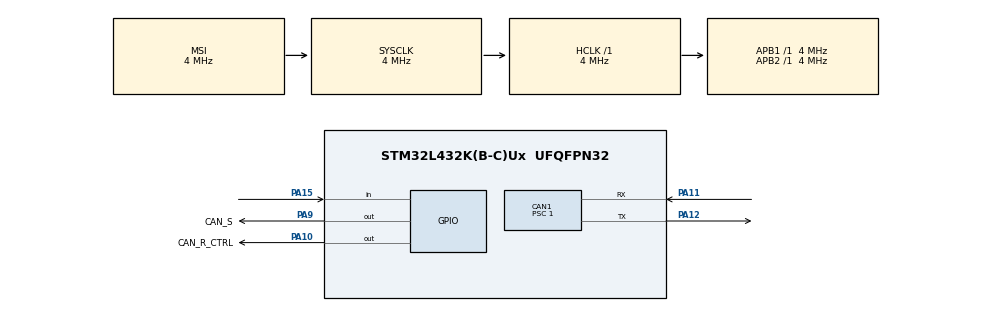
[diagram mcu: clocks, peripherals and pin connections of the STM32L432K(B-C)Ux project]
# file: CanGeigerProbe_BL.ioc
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CAN1.BS1=CAN_BS1_6TQ
CAN1.CalculateBaudRate=500000
CAN1.CalculateTimeBit=2000
CAN1.CalculateTimeQuantum=250.0
CAN1.NART=ENABLE
CAN1.Prescaler=1
Mcu.Family=STM32L4
Mcu.Name=STM32L432K(B-C)Ux
Mcu.Package=UFQFPN32
NVIC.CAN1_RX0_IRQn=true\:0\:0\:false\:false\:true\:true\:true\:true
NVIC.CAN1_TX_IRQn=true\:0\:0\:false\:false\:true\:true\:true\:true
NVIC.PriorityGroup=NVIC_PRIORITYGROUP_4
PA10.GPIO_Label=CAN_R_CTRL
PA10.Signal=GPIO_Output
PA11.Mode=CAN_Activate
PA11.Signal=CAN1_RX
PA12.Mode=CAN_Activate
PA12.Signal=CAN1_TX
PA13\ (JTMS-SWDIO).GPIO_Label=SWDIO
PA13\ (JTMS-SWDIO).Mode=Trace_Asynchronous_SW
PA13\ (JTMS-SWDIO).Signal=SYS_JTMS-SWDIO
PA14\ (JTCK-SWCLK).GPIO_Label=SWCLK
PA14\ (JTCK-SWCLK).Mode=Trace_Asynchronous_SW
PA14\ (JTCK-SWCLK).Signal=SYS_JTCK-SWCLK
PA15\ (JTDI).Signal=GPIO_Input
PA9.GPIO_Label=CAN_S
PA9.Signal=GPIO_Output
PB3\ (JTDO-TRACESWO).GPIO_Label=SWO
PB3\ (JTDO-TRACESWO).Mode=Trace_Asynchronous_SW
PB3\ (JTDO-TRACESWO).Signal=SYS_JTDO-SWO
ProjectManager.HeapSize=0x200
ProjectManager.StackSize=0x400
ProjectManager.TargetToolchain=STM32CubeIDE
RCC.ADCCLockSelection=RCC_ADCCLKSOURCE_SYSCLK
RCC.ADCFreq_Value=4000000
RCC.AHBFreq_Value=4000000
RCC.APB1Freq_Value=4000000
RCC.APB1TimFreq_Value=4000000
RCC.APB2Freq_Value=4000000
RCC.APB2TimFreq_Value=4000000
RCC.CortexFreq_Value=4000000
RCC.HCLKFreq_Value=4000000
RCC.HSE_VALUE=8000000
RCC.HSI48_VALUE=48000000
RCC.HSI_VALUE=16000000
RCC.I2C1CLockSelection=RCC_I2C1CLKSOURCE_SYSCLK
RCC.LSE_VALUE=32768
RCC.MSI_VALUE=4000000
RCC.SYSCLKFreq_VALUE=4000000
RCC.USBFreq_Value=16000000
RCC.VCOOutputFreq_Value=32000000
board=custom

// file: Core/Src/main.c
/* USER CODE BEGIN Header */
/**
  ******************************************************************************
  * @file           : main.c
  * @brief          : Main program body
  ******************************************************************************
  * @attention
  *
  * Copyright (c) 2026 STMicroelectronics.
  * All rights reserved.
  *
  * This software is licensed under terms that can be found in the LICENSE file
  * in the root directory of this software component.
  * If no LICENSE file comes with this software, it is provided AS-IS.
  *
  ******************************************************************************
  */
/* USER CODE END Header */
#include "main.h"

/* USER CODE BEGIN Includes */
#include "bl.h"

/* USER CODE END Includes */

CAN_HandleTypeDef hcan1;

void SystemClock_Config(void);
static void MX_GPIO_Init(void);
static void MX_CAN1_Init(void);

int main(void)
{

  /* MCU Configuration--------------------------------------------------------*/

  /* Reset of all peripherals, Initializes the Flash interface and the Systick. */
  HAL_Init();

  /* Configure the system clock */
  SystemClock_Config();

  /* Initialize all configured peripherals */
  MX_GPIO_Init();
  MX_CAN1_Init();
  /* USER CODE BEGIN 2 */
  bl_core_run(&hcan1);   /* bootloader — nie wraca (skok do aplikacji albo programowanie) */

  /* USER CODE END 2 */

  /* Infinite loop */
  while (1)
  {

  }
}

void SystemClock_Config(void)
{
  RCC_OscInitTypeDef RCC_OscInitStruct = {0};
  RCC_ClkInitTypeDef RCC_ClkInitStruct = {0};

  /** Configure the main internal regulator output voltage
  */
  if (HAL_PWREx_ControlVoltageScaling(PWR_REGULATOR_VOLTAGE_SCALE1) != HAL_OK)
  {
    Error_Handler();
  }

  /** Initializes the RCC Oscillators according to the specified parameters
  * in the RCC_OscInitTypeDef structure.
  */
  RCC_OscInitStruct.OscillatorType = RCC_OSCILLATORTYPE_MSI;
  RCC_OscInitStruct.MSIState = RCC_MSI_ON;
  RCC_OscInitStruct.MSICalibrationValue = 0;
  RCC_OscInitStruct.MSIClockRange = RCC_MSIRANGE_6;
  RCC_OscInitStruct.PLL.PLLState = RCC_PLL_NONE;
  if (HAL_RCC_OscConfig(&RCC_OscInitStruct) != HAL_OK)
  {
    Error_Handler();
  }

  /** Initializes the CPU, AHB and APB buses clocks
  */
  RCC_ClkInitStruct.ClockType = RCC_CLOCKTYPE_HCLK|RCC_CLOCKTYPE_SYSCLK
                              |RCC_CLOCKTYPE_PCLK1|RCC_CLOCKTYPE_PCLK2;
  RCC_ClkInitStruct.SYSCLKSource = RCC_SYSCLKSOURCE_MSI;
  RCC_ClkInitStruct.AHBCLKDivider = RCC_SYSCLK_DIV1;
  RCC_ClkInitStruct.APB1CLKDivider = RCC_HCLK_DIV1;
  RCC_ClkInitStruct.APB2CLKDivider = RCC_HCLK_DIV1;

  if (HAL_RCC_ClockConfig(&RCC_ClkInitStruct, FLASH_LATENCY_0) != HAL_OK)
  {
    Error_Handler();
  }
}

static void MX_CAN1_Init(void)
{

  hcan1.Instance = CAN1;
  hcan1.Init.Prescaler = 1;
  hcan1.Init.Mode = CAN_MODE_NORMAL;
  hcan1.Init.SyncJumpWidth = CAN_SJW_1TQ;
  hcan1.Init.TimeSeg1 = CAN_BS1_6TQ;
  hcan1.Init.TimeSeg2 = CAN_BS2_1TQ;
  hcan1.Init.TimeTriggeredMode = DISABLE;
  hcan1.Init.AutoBusOff = DISABLE;
  hcan1.Init.AutoWakeUp = DISABLE;
  hcan1.Init.AutoRetransmission = ENABLE;
  hcan1.Init.ReceiveFifoLocked = DISABLE;
  hcan1.Init.TransmitFifoPriority = DISABLE;
  if (HAL_CAN_Init(&hcan1) != HAL_OK)
  {
    Error_Handler();
  }

}

static void MX_GPIO_Init(void)
{
  GPIO_InitTypeDef GPIO_InitStruct = {0};

  /* GPIO Ports Clock Enable */
  __HAL_RCC_GPIOA_CLK_ENABLE();
  __HAL_RCC_GPIOB_CLK_ENABLE();

  /*Configure GPIO pin Output Level */
  HAL_GPIO_WritePin(GPIOA, CAN_S_Pin|CAN_R_CTRL_Pin, GPIO_PIN_RESET);

  /*Configure GPIO pins : CAN_S_Pin CAN_R_CTRL_Pin */
  GPIO_InitStruct.Pin = CAN_S_Pin|CAN_R_CTRL_Pin;
  GPIO_InitStruct.Mode = GPIO_MODE_OUTPUT_PP;
  GPIO_InitStruct.Pull = GPIO_NOPULL;
  GPIO_InitStruct.Speed = GPIO_SPEED_FREQ_LOW;
  HAL_GPIO_Init(GPIOA, &GPIO_InitStruct);

  /*Configure GPIO pin : PA15 */
  GPIO_InitStruct.Pin = GPIO_PIN_15;
  GPIO_InitStruct.Mode = GPIO_MODE_INPUT;
  GPIO_InitStruct.Pull = GPIO_NOPULL;
  HAL_GPIO_Init(GPIOA, &GPIO_InitStruct);

}

void Error_Handler(void)
{
  __disable_irq();
  while (1)
  {
  }
}
